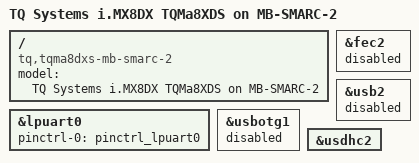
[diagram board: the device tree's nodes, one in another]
/*
 * Copyright 2019 TQ Systems GmbH
 *
 * This program is free software; you can redistribute it and/or
 * modify it under the terms of the GNU General Public License
 * as published by the Free Software Foundation; either version 2
 * of the License, or (at your option) any later version.
 *
 * This program is distributed in the hope that it will be useful,
 * but WITHOUT ANY WARRANTY; without even the implied warranty of
 * MERCHANTABILITY or FITNESS FOR A PARTICULAR PURPOSE.  See the
 * GNU General Public License for more details.
 */

#include "fsl-imx8qxp-tqma8qxps-mb-smarc-2.dts"

/ {
	model = "TQ Systems i.MX8DX TQMa8XDS on MB-SMARC-2";
	compatible = "tq,tqma8dxs-mb-smarc-2", "tq,tqma8dxs", "fsl,imx8qxp";
};

&fec2 {
	status = "disabled";
};

&lpuart0 {
	pinctrl-names = "default";
	pinctrl-0 = <&pinctrl_lpuart0>;
	status = "okay";
};

&usbotg1 {
	status = "disabled";
};

&usb2 {
	status = "disabled";
};

&usdhc2 {
	status = "okay";
};
